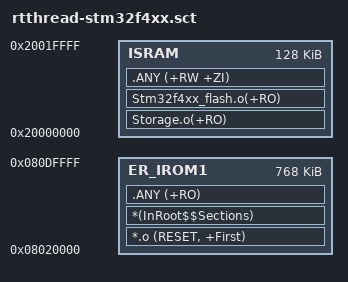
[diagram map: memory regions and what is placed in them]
; *************************************************************
; *** Scatter-Loading Description File generated by uVision ***
; *************************************************************

LR_IROM1 0x08020000 0x000C0000  {    ; load region size_region
  ER_IROM1 0x08020000 0x000C0000  {  ; load address = execution address
   *.o (RESET, +First)
   *(InRoot$$Sections)
   .ANY (+RO)
  }
  ISRAM 0x20000000 0x00020000  {  ; RW data
   Storage.o(+RO)
   Stm32f4xx_flash.o(+RO)
   .ANY (+RW +ZI)
  }
}

